# PKA_0.0 register map
Vendor: Texas Instruments
Peripheral module from a debugger description file (folder mspm33c321x).
Registers are 32-bit, read-write, no defined reset value unless marked. A register's access mark holds for its fields unless they carry their own. Offsets are as the file gives them; lines under a group give offsets from that group; [hi:lo] are bit positions; {n}, {i} and the like mark numbered series; 'fields as' and 'values as' point back to an identical list; <NAME> marks a mode.

## PKA
0x800 PKA_GPRCM group
  0x00 PKA_PWREN — Power enable
    [0] ENABLE — Enable the power
      0=DISABLE (Disable Power); 1=ENABLE (Enable Power)
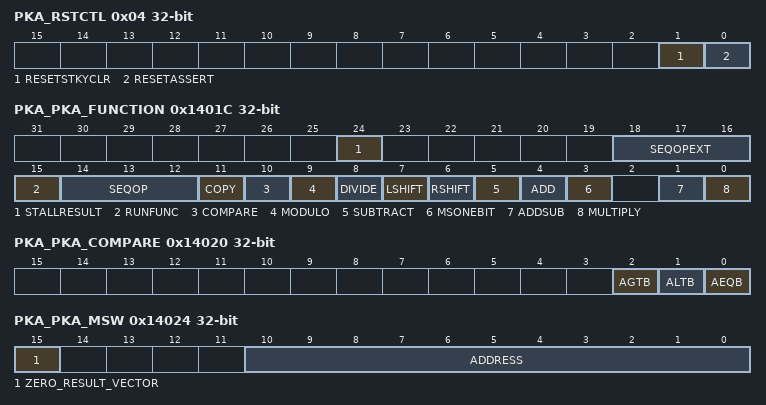
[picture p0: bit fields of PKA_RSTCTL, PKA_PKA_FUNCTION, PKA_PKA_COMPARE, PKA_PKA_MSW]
  0x04 PKA_RSTCTL — Reset Control
    [1] RESETSTKYCLR — Clear the RESETSTKY bit in the STAT register
      0=NOP (Writing 0 has no effect); 1=CLR (Clear reset sticky bit)
    [0] RESETASSERT — Assert reset to the peripheral
      0=NOP (Writing 0 has no effect); 1=ASSERT (Assert reset)
  0x14 PKA_STAT ro — Status Register
    [16] RESETSTKY — This bit indicates, if the peripheral was reset, since this bit was cleared by RESETSTKYCLR in the RSTCTL register
      0=NORES (The peripheral has not been reset since this bit was last cleared by RESETSTKYCLR in the RSTCTL register); 1=RESET (The peripheral was reset since the last bit clear)
0x14000 PKA_PKA_APTR — A operand address offset
  [10:0] APTR — This register specifies the location of Vector A within the PKA Data RAM. Vectors are identified through the location of their least-significant 32-bit word. Note that bit [0] must be zero to ensure that the vector starts at an 8-byte boundary
0x14004 PKA_PKA_BPTR — B operand address offset
  [10:0] BPTR — This register specifies the location of Vector B within the PKA Data RAM. Vectors are identified through the location of their least-significant 32-bit word. Note that bit [0] must be zero to ensure that the vector starts at an 8-byte boundary
0x14008 PKA_PKA_CPTR — C operand address offset
  [10:0] CPTR — This register specifies the location of Vector C within the PKA Data RAM. Vectors are identified through the location of their least-significant 32-bit word. Note that bit [0] must be zero to ensure that the vector starts at an 8-byte boundary
0x1400C PKA_PKA_DPTR — D operand address offset
  [10:0] DPTR — This register specifies the location of Vector D within the PKA Data RAM. Vectors are identified through the location of their least-significant 32-bit word. Note that bit [0] must be zero to ensure that the vector starts at an 8-byte boundary
0x14010 PKA_PKA_ALENGTH — Length of A operand
  [9:0] ALENGTH — This register specifies the length (in 32-bit words) of Vector A
0x14014 PKA_PKA_BLENGTH — Length of B operand
  [9:0] PKA_BLENGTH — This register specifies the length (in 32-bit words) of Vector B
0x14018 PKA_PKA_SHIFT — Bits to shift
  [4:0] BITS_TO_SHIFT — This register specifies the number of bits to shift the input vector in the range 0 to 31 during a Rshift or Lshift operation
0x1401C PKA_PKA_FUNCTION — control bits to start basic PKCP as well as complex Sequencer operations
  [24] STALLRESULT — When written with a 1b, updating of the PKA_COMPARE, PKA_MSW and PKA_DIVMSW registers, as well as resetting the Run bit is stalled beyond the point that a running operation is finished
  [18:16] SEQOPEXT — These bits select the complex Sequencer operation to perform. The encoding of these operations is determined by the Sequencer firmware
  [15] RUNFUNC — The Host sets this bit to instruct the PKA module to begin processing the basic PKCP or complex Sequencer operation. This bit is reset low automatically when the operation is complete
  [14:12] SEQOP — These bits select the complex Sequencer operation to perform. The encoding of these operations is determined by the Sequencer firmware
  [11] COPY — Perform copy operation
  [10] COMPARE — Perform compare operation
  [9] MODULO — Perform modulo operation
  [8] DIVIDE — Perform divide operation
  [7] LSHIFT — Perform left shift operation
  [6] RSHIFT — Perform right shift operation
  [5] SUBTRACT — Perform subtract operation
  [4] ADD — Perform add operation.
  [3] MSONEBIT — Loads the location of the Most Significant one bit within the result word indicated in the PKA_MSW register into bits [4:0] of the PKA_DIVMSW register, can only be used with basic PKCP operations, except for Divide, Modulo and Compare
  [1] ADDSUB — Perform combined add, subtract operation
  [0] MULTIPLY — Perform multiply operation
0x14020 PKA_PKA_COMPARE ro — Result of compare
  [2] AGTB — Vector A > Vector B
  [1] ALTB — Vector A < Vector B
  [0] AEQB — Vector A = Vector B
0x14024 PKA_PKA_MSW ro — MS non-zero word address
  [15] ZERO_RESULT_VECTOR — The result vector is all zeroes, ignore the address returned in bits 10 to 0
  [10:0] ADDRESS — Address of the most significant non zero 32 bit word of the result vector in PKA Data RAM
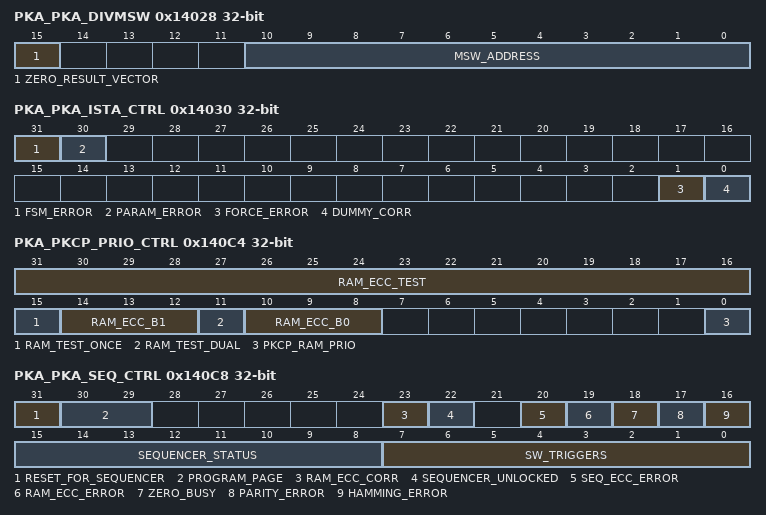
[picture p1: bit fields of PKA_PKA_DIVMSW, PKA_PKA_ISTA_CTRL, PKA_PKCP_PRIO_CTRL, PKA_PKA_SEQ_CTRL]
0x14028 PKA_PKA_DIVMSW ro — MS non-zero word address for remainder (MOD and DIV ops)
  [15] ZERO_RESULT_VECTOR — The remainder result vector is all zeroes, ignore the address returned in bits 10 to 0
  [10:0] MSW_ADDRESS — Address of the most significant nonzero 32 bit word of the Remainder result vector in PKA Data RAM
0x14030 PKA_PKA_ISTA_CTRL — This register provides control and status bits related to the Illegal State and Timing Attack features of the PKCP
  [31] FSM_ERROR — This bit is set to 1b when one of the PKCP control FSMs enters an illegal state
  [30] PARAM_ERROR — This bit is set to 1b when an illegal operation code selecting more than 1 operation at a time is written to the PKA_FUNCTION register. It is also set to 1b when the highest 32-bit word of the B vector (divisor) input to a PKCP DIV or MOD operation equals zero MOD operation equals zero
  [1] FORCE_ERROR — 1b = force FSM errors, eg jump to an illegal state, when starting basic PKCP operations, these should activate the fsm_error bit in this register
  [0] DUMMY_CORR — 1b = enable dummy correction cycles in the basic PKCP DIV and MOD operations. These dummy cycles remove the variability of these operations at the cost of a running time that can be up to around 70 percent longer
0x140C4 PKA_PKCP_PRIO_CTRL — PKCP or Sequencer RAM Access Priority Control
  [31:16] RAM_ECC_TEST — Depending on ram_test_dual, internal registers ram_ecc_test_0 and ram_ecc_test_1 will be set, or only ram_ecc_test_0
  [15] RAM_TEST_ONCE — Writing 1b inserts errors only once, on the next write to the PKA Data RAM, all the ram_ecc_test bits will be reset to zero to prevent further error insertions
  [14:12] RAM_ECC_B1 — Bit number for bit to flip in Bytes selected in field ram_ecc_test_1
  [11] RAM_TEST_DUAL — Set this bit to 1b to produce dual errors, prior to setting ram_ecc_test. When this bit is enabled the next write to ram_ecc_test will set internal registers ram_ecc_test_0 and ram_ecc_test_1, When set to 0b, only ram_ecc_test_0 will be set
  [10:8] RAM_ECC_B0 — Bit number for bit to flip in Bytes selected in field ram_ecc_test_0
  [0] PKCP_RAM_PRIO — 0b = Sequencer has priority for accessing data RAM. 1b = PKCP has priority for accessing data RAM.
0x140C8 PKA_PKA_SEQ_CTRL access per field — PKA Squencer control or status
  [31] RESET_FOR_SEQUENCER rw
  [30:29] PROGRAM_PAGE rw — This field provides two page select bits for accessing the Sequencer program RAM through the Host interface when that is larger than 2K words. Value 00b selects page 0, the lowest page, value 01b selects page 1, etcetera
  [23] RAM_ECC_CORR rw — Overall correctable RAM SECDED EDC error detected status bit.
  [22] SEQUENCER_UNLOCKED rw — This bit is set to 1b when the main Sequencer receives a SW reset during a complex operation, thereby unlocking the Sequencer. The bit is sticky: It can be cleared again by writing a 1b to this location. Writing a 0b has no effect
  [20] SEQ_ECC_ERROR rw — Sequencer uncorrectable RAM SECDED EDC error. This bit reads 1b when an uncorrectable error occurred while the Sequencer reads the PKA Data RAM
  [19] RAM_ECC_ERROR rw — Overall uncorrectable RAM SECDED EDC error status bit,This bit reads 1b when one or more uncorrectable error(s) occurred on the PKA #br#Data RAM
  [18] ZERO_BUSY ro — When 1b is returned this read only bit indicates that the zeroization logic is busy. During zeroization the PKA cannot be used
  [17] PARITY_ERROR rw — A 1b indicates parity error was detected
  [16] HAMMING_ERROR rw — A 1b indicates a mismatch was detected between bits 28:24 of a Sequencer instruction word and the Hamming protection code calculated from bits 23:0 of that same instruction word. This Hamming code detects at least 2 bit errors in bits 23:0. The state of this bit is OR-ed into the protection_int output of the engine
  [15:8] SEQUENCER_STATUS ro — These read only bits are used by the Sequencer to communicate status to the outside world. Bit 8 is also used as Sequencer interrupt, with the complement of this bit OR-ed into the Run bit in PKA_FUNCTION
  [7:0] SW_TRIGGERS rw — These bits can be used by software to trigger Sequencer operations
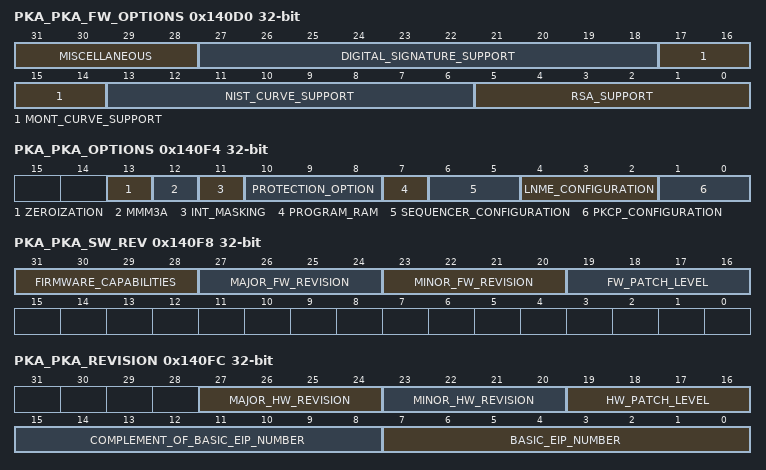
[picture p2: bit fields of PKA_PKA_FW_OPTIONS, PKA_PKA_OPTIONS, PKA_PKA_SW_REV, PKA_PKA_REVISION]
0x140D0 PKA_PKA_FW_OPTIONS ro — FW options register
  [31:28] MISCELLANEOUS — xxx1 : Reserved for Binary curve support xx1x : Reserved for SCAP functionality extension x1xx : Fixed-Point ECp multiplication is supported 1xxx : Shamirs trick is configured for ECDSApVERIFY and SM2DSApVERIFY
  [27:18] DIGITAL_SIGNATURE_SUPPORT — xxxxxxxxx1 : DSASIGN is supported xxxxxxxx1x : DSAVERIFY is supported xxxxxxx1xx : ECDSApSIGN is supported xxxxxx1xxx : ECDSApVERIFY is supported xxxxx1xxxx : SM2DSApSIGN is supported xxxx1xxxxx : SM2DSApVERIFY is supported xxx1xxxxxx : Reserved for SCAP command xx1xxxxxxx : ditto x1xxxxxxxx : ditto 1xxxxxxxxx : ditto
  [17:14] MONT_CURVE_SUPPORT — xxx1 : ECmontMUL is supported xx1x : Reserved for SCAP command x1xx : Not used, reserved for future use 1xxx : ditto
  [13:6] NIST_CURVE_SUPPORT — xxxxxxx1 : ECpMUL is supported xxxxxx1x : ECpMULxyz is supported xxxxx1xx : Reserved for SCAP command xxxx1xxx : ECpADD is supported xxx1xxxx : ECpADDxyz is supported xx1xxxxx : Not used, reserved for future use x1xxxxxx : ditto 1xxxxxxx : ditto
  [5:0] RSA_SUPPORT — xxxxx1 : ModExp is supported xxxx1x : ModExpCRT is supported xxx1xx : ModInv is supported xx1xxx : Reserved for SCAP command x1xxxx : ditto 1xxxxx : ditto
0x140F4 PKA_PKA_OPTIONS ro — HW configured options
  [13] ZEROIZATION — Value 1b indicates that hardware zeroization logic is present
  [12] MMM3A — When an LNME is present, this bit is 1b to indicate the MMM3A operation is implemented, otherwise this bit equals 0b
  [11] INT_MASKING — Value 0b (default) indicates that the main interrupt output (bit [1] of the interrupts output bus) is the direct complement of the Run bit in the PKA_CONTROL register, value 1b indicates that interrupt masking logic is present for this output.
  [10:8] PROTECTION_OPTION — Value 0 indicates that no additional protection features are present. Value 1 indicates that Illegal State and Timing Attack (ISTA) protection features are present. Value 3 indicates that ISTA protection features are present together with the PROT feature (detection of invalid Sequencer opcodes). Other values are reserved
  [7] PROGRAM_RAM — Value 1b indicates Sequencer program storage in RAM, value 0b in ROM
  [6:5] SEQUENCER_CONFIGURATION — Value 1 indicates a standard Sequencer, other values reserved.
  [4:2] LNME_CONFIGURATION — Value 0 indicates NO LNME, value 1 indicates a standard LNME (with a single PE chain), value 2 indicates a dual LNME (with two parallel PE chains), other values reserved
  [1:0] PKCP_CONFIGURATION — Value 1 indicates a PKCP with a 16x16 multiplier, value 2 indicates a PKCP with a 32x32 multiplier, other values reserved
0x140F8 PKA_PKA_SW_REV ro — FW revision numbers, capabilities
  [31:28] FIRMWARE_CAPABILITIES — 4 bits binary encoding for the functionality implemented in the firmware
  [27:24] MAJOR_FW_REVISION — 4 bits binary encoding of the major firmware revision number
  [23:20] MINOR_FW_REVISION — 4 bits binary encoding of the minor firmware revision number
  [19:16] FW_PATCH_LEVEL — 4 bits binary encoding of the firmware patch level, initial release will carry value zero. Patches are used to remove bugs without changing the functionality or interface of a module
0x140FC PKA_PKA_REVISION ro — PKA HW revision, EIP code
  [27:24] MAJOR_HW_REVISION — 4 bits binary encoding of the major hardware revision number
  [23:20] MINOR_HW_REVISION — 4 bits binary encoding of the minor hardware revision number
  [19:16] HW_PATCH_LEVEL — 4 bits binary encoding of the hardware patch level, initial release will carry value zero. Patches are used to remove bugs without changing the functionality or interface of a module
  [15:8] COMPLEMENT_OF_BASIC_EIP_NUMBER — Bit-by-bit logic complement of bits [7:0], EIP-28 gives 0xE3
  [7:0] BASIC_EIP_NUMBER — 8 bits binary encoding of the EIP number, EIP-28 gives 0x1C
{0x16000+4i} PKA_PKA_RAM_DATA[{i}] (i=0..511) access not given — PKA DATA RAM - 512 Locations - 2KB
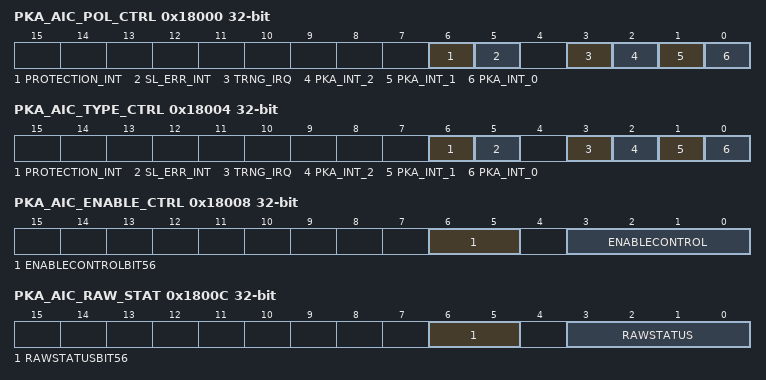
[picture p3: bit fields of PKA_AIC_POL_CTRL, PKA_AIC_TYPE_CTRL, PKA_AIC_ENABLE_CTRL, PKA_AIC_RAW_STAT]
0x18000 PKA_AIC_POL_CTRL — Input Polarity Control Register
  [6] PROTECTION_INT — 1 = high level/rising edge
  [5] SL_ERR_INT — 1 = high level/rising edge
  [3] TRNG_IRQ — 1 = high level/rising edge
  [2] PKA_INT_2 — 1 = high level/rising edge
  [1] PKA_INT_1 — 1 = high level/rising edge
  [0] PKA_INT_0 — 1 = high level/rising edge
0x18004 PKA_AIC_TYPE_CTRL — Input Type Control Register
  [6] PROTECTION_INT — 1 = Edge
  [5] SL_ERR_INT — 1 = Edge
  [3] TRNG_IRQ — 1 = Edge
  [2] PKA_INT_2 — 1 = Edge
  [1] PKA_INT_1 — 1 = Edge
  [0] PKA_INT_0 — 1 = Edge
0x18008 PKA_AIC_ENABLE_CTRL — Interrupt Enable Control Register
  [6:5] ENABLECONTROLBIT56 — 0 = Disabled 1 = Enabled
  [3:0] ENABLECONTROL — 0 = Disabled 1 = Enabled
0x1800C PKA_AIC_RAW_STAT ro — Raw Interrupt Pending Status Register
  [6:5] RAWSTATUSBIT56 — 0 = Inactive 1 = Pending
  [3:0] RAWSTATUS — 0 = Inactive 1 = Pending
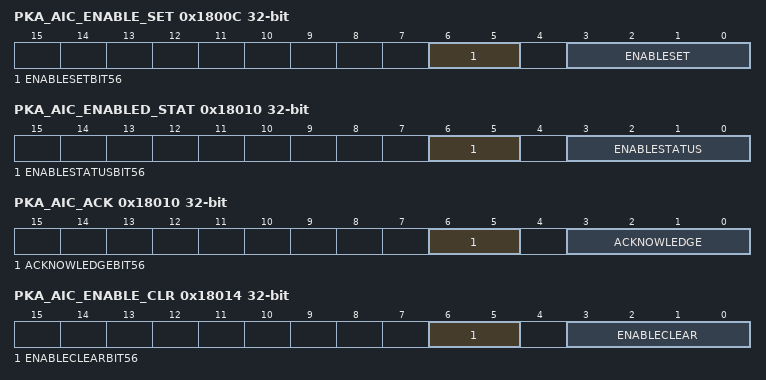
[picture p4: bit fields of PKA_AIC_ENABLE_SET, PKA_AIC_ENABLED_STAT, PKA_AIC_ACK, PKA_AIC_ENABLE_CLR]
0x1800C PKA_AIC_ENABLE_SET — Interrupt Enable Register
  [6:5] ENABLESETBIT56 — 0 = Inactive 1 = Pending
  [3:0] ENABLESET — 0 = Inactive 1 = Pending
0x18010 PKA_AIC_ENABLED_STAT ro — Masked Interrupt Pending Status Register
  [6:5] ENABLESTATUSBIT56 — 0 = Inactive 1 = Pending
  [3:0] ENABLESTATUS — 0 = Inactive 1 = Pending
0x18010 PKA_AIC_ACK — Interrupt Acknowledge Register
  [6:5] ACKNOWLEDGEBIT56 — 0 = No effect. 1 = Acknowledge the interrupt signal, clears the status bit. The activated bit of Acknowledge will be cleared internally
  [3:0] ACKNOWLEDGE — 0 = No effect. 1 = Acknowledge the interrupt signal, clears the status bit. The activated bit of Acknowledge will be cleared internally
0x18014 PKA_AIC_ENABLE_CLR — Interrupt Disable Register
  [6:5] ENABLECLEARBIT56 — 0 = No effect. 1 = Acknowledge the interrupt signal, clears the status bit. The activated bit of Acknowledge will be cleared internally
  [3:0] ENABLECLEAR — Individual interrupt disable bits per interrupt input 0 = No effect. 1 = Resets the corresponding bit in the AIC_ENABLE_CTRL register to '0', i.e. disables that interrupt. The activated bit of EnableClear will be cleared internally
0x18018 PKA_AIC_OPTIONS ro — AIC Configuration Register
  [5:0] NUMBER_OF_INPUTS — The EIP-201 supports up to 32 interrupt sources but the EIP-150 only has a maximum of 7 internal interrupt sources when all options are present: PKA (3), TRNG (1), reserved for backward compatibility (1), bus interface error (1) and PKA protection (1).
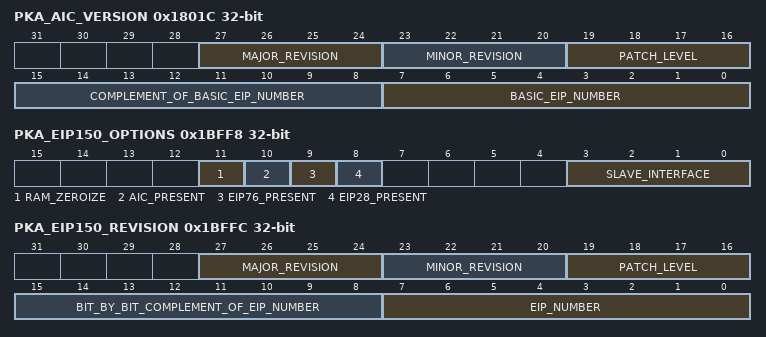
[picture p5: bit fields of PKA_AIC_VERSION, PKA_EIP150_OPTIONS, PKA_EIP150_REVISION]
0x1801C PKA_AIC_VERSION ro — AIC HW revision, EIP code
  [27:24] MAJOR_REVISION — These bits encode the major version number for this module
  [23:20] MINOR_REVISION — These bits encode the minor version number for this module
  [19:16] PATCH_LEVEL — These bits encode the hardware patch level for this module they start at value 0 on the first release
  [15:8] COMPLEMENT_OF_BASIC_EIP_NUMBER — These bits simply contain the complement of bits [7:0] (0x36), used by a driver to ascertain that the AIC_VERSION register is indeed read
  [7:0] BASIC_EIP_NUMBER — These bits encode the Rambus EIP number for the AIC. As the AIC is called the EIP-201 in Rambuss IP numbering so this field contains the value 201 (decimal) or 0xC9
0x1BFF8 PKA_EIP150_OPTIONS ro — PKP Configuration Register
  [11] RAM_ZEROIZE — When set to 1: indicates that PKA/LMNE RAM ZEROIZE logic is present
  [10] AIC_PRESENT — When set to 1: indicates that an EIP-201 AIC is included in the EIP-150
  [9] EIP76_PRESENT — When set to 1: indicates that an EIP-76 TRNG is included in the EIP-150
  [8] EIP28_PRESENT — When set to 1: indicates that an EIP-28 PKA is included in the EIP-150
  [3:0] SLAVE_INTERFACE — This field decodes the type slave interface that used for the EIP-150. 0b0001 : AHB slave interface. 0b0011 : AXI slave interface. 0b1001 : Asynchronous AHB slave interface. 0b1101 : Asynchronous APB slave interface. Other values are reserved for future use
0x1BFFC PKA_EIP150_REVISION ro — PKP HW revision, EIP code
  [27:24] MAJOR_REVISION — These bits encode the major version number for this module
  [23:20] MINOR_REVISION — These bits encode the minor version number for this module
  [19:16] PATCH_LEVEL — encoding for hardware patch level, they start at value 0 on the first release
  [15:8] BIT_BY_BIT_COMPLEMENT_OF_EIP_NUMBER — These bits simply contain the complement of bits 7 down to 0 used by a driver to ascertain that the EIP150_REVISION register is indeed read
  [7:0] EIP_NUMBER — These bits encode the Rambus EIP number for the EIP-150
